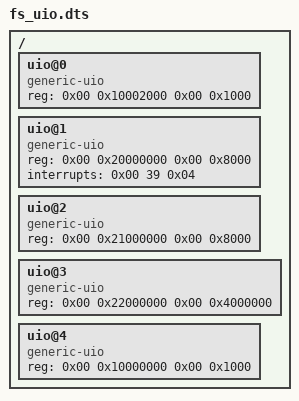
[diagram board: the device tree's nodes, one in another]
/*
 * Copyright 2024, UNSW
 *
 * SPDX-License-Identifier: BSD-2-Clause
 */
/ {
    // All of these paddrs are arbitrarily chosen.
    // The only consideration is that you don't hit any other
    // physical device region or the guest RAM.
    uio@0 {
        // config data
        compatible = "generic-uio\0vmfs_config";
        reg = <0x00 0x10002000 0x00 0x1000>;
    };

    uio@1 {
        // fs_command_queue and client IRQ
        compatible = "generic-uio\0vmfs_command";
        reg = <0x00 0x20000000 0x00 0x8000>;
        interrupts = <0x00 39 0x04>;
        // IRQ = uKit 71 (39 + 32)
    };

    uio@2 {
        // fs_completion_queue
        compatible = "generic-uio\0vmfs_completion";
        reg = <0x00 0x21000000 0x00 0x8000>;
    };

    uio@3 {
        // shared_fs_data
        compatible = "generic-uio\0vmfs_data";
        reg = <0x00 0x22000000 0x00 0x4000000>;
    };

    uio@4 {
        // guest to vmm fault region, this must be unmapped in SDF.
        compatible = "generic-uio\0vmfs_fault";
        reg = <0x00 0x10000000 0x00 0x1000>;
    };
};
